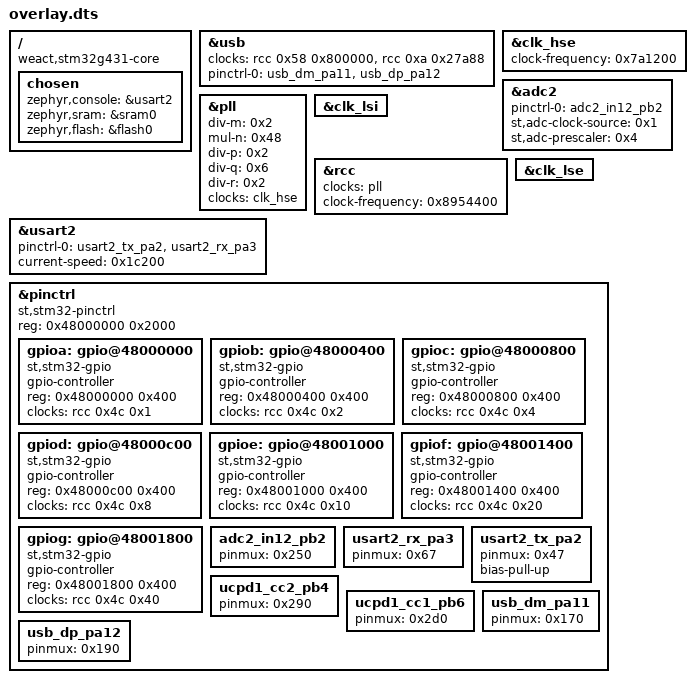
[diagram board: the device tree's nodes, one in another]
/ {
	compatible = "weact,stm32g431-core";
	chosen {
		zephyr,console = &usart2;
		zephyr,sram = &sram0;
		zephyr,flash = &flash0;
	};
};
&usb{
	clocks = < &rcc 0x58 0x800000 >, < &rcc 0xa 0x27a88 >;
	status = "okay";
	pinctrl-0 = < &usb_dm_pa11 &usb_dp_pa12 >;
	pinctrl-names = "default";
};
&clk_hse{
	status = "okay";
	clock-frequency = < 0x7a1200 >;
};
&adc2{
	pinctrl-0 = < &adc2_in12_pb2 >;
	pinctrl-names = "default";
	st,adc-clock-source = < 0x1 >;
	st,adc-prescaler = < 0x4 >;
	#address-cells = < 0x1 >;
	#size-cells = < 0x0 >;
};
&pll{
	status = "okay";
	div-m = < 0x2 >;
	mul-n = < 0x48 >;
	div-p = < 0x2 >;
	div-q = < 0x6 >;
	div-r = < 0x2 >;
	clocks = < &clk_hse >;
};
&clk_lsi{
	status = "okay";
};
&rcc{
	clocks = < &pll >;
	clock-frequency = < 0x8954400 >;
};
&clk_lse{
	status = "okay";
};
&usart2{
	status = "okay";
	pinctrl-0 = < &usart2_tx_pa2 &usart2_rx_pa3 >;
	pinctrl-names = "default";
	current-speed = < 0x1c200 >;
};
&pinctrl{
	compatible = "st,stm32-pinctrl";
	#address-cells = < 0x1 >;
	#size-cells = < 0x1 >;
	reg = < 0x48000000 0x2000 >;
	gpioa: gpio@48000000 {
		compatible = "st,stm32-gpio";
		gpio-controller;
		#gpio-cells = < 0x2 >;
		reg = < 0x48000000 0x400 >;
		clocks = < &rcc 0x4c 0x1 >;
	};
	gpiob: gpio@48000400 {
		compatible = "st,stm32-gpio";
		gpio-controller;
		#gpio-cells = < 0x2 >;
		reg = < 0x48000400 0x400 >;
		clocks = < &rcc 0x4c 0x2 >;
	};
	gpioc: gpio@48000800 {
		compatible = "st,stm32-gpio";
		gpio-controller;
		#gpio-cells = < 0x2 >;
		reg = < 0x48000800 0x400 >;
		clocks = < &rcc 0x4c 0x4 >;
	};
	gpiod: gpio@48000c00 {
		compatible = "st,stm32-gpio";
		gpio-controller;
		#gpio-cells = < 0x2 >;
		reg = < 0x48000c00 0x400 >;
		clocks = < &rcc 0x4c 0x8 >;
	};
	gpioe: gpio@48001000 {
		compatible = "st,stm32-gpio";
		gpio-controller;
		#gpio-cells = < 0x2 >;
		reg = < 0x48001000 0x400 >;
		clocks = < &rcc 0x4c 0x10 >;
	};
	gpiof: gpio@48001400 {
		compatible = "st,stm32-gpio";
		gpio-controller;
		#gpio-cells = < 0x2 >;
		reg = < 0x48001400 0x400 >;
		clocks = < &rcc 0x4c 0x20 >;
	};
	gpiog: gpio@48001800 {
		compatible = "st,stm32-gpio";
		gpio-controller;
		#gpio-cells = < 0x2 >;
		reg = < 0x48001800 0x400 >;
		clocks = < &rcc 0x4c 0x40 >;
	};
	adc2_in12_pb2: adc2_in12_pb2 {
		pinmux = < 0x250 >;
	};
	usart2_rx_pa3: usart2_rx_pa3 {
		pinmux = < 0x67 >;
	};
	usart2_tx_pa2: usart2_tx_pa2 {
		pinmux = < 0x47 >;
		bias-pull-up;
	};
	ucpd1_cc2_pb4: ucpd1_cc2_pb4 {
		pinmux = < 0x290 >;
	};
	ucpd1_cc1_pb6: ucpd1_cc1_pb6 {
		pinmux = < 0x2d0 >;
	};
	usb_dm_pa11: usb_dm_pa11 {
		pinmux = < 0x170 >;
	};
	usb_dp_pa12: usb_dp_pa12 {
		pinmux = < 0x190 >;
	};
};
